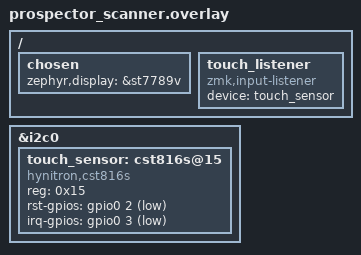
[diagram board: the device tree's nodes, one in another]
/ {
   chosen {
      zephyr,display = &st7789v;
  };
};

&i2c0 {
   status = "okay";
    touch_sensor: cst816s@15 {
        compatible = "hynitron,cst816s";
        reg = <0x15>;
        status = "okay";
        rst-gpios = <&gpio0 2 GPIO_ACTIVE_LOW>;   // D0 = P0.02
        irq-gpios = <&gpio0 3 GPIO_ACTIVE_LOW>;   // D1 = P0.03
    };
};

/ {
    touch_listener: touch_listener {
        status = "okay";
        compatible = "zmk,input-listener";
        device = <&touch_sensor>;
    };
};
